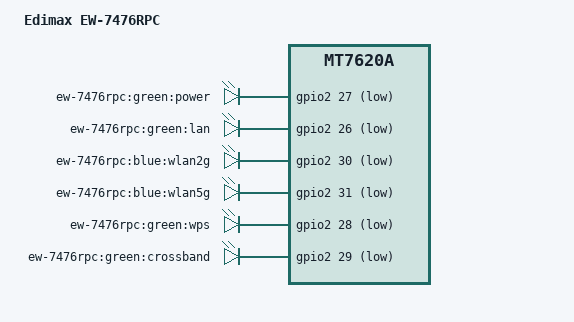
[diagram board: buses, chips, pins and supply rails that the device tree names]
// SPDX-License-Identifier: GPL-2.0-or-later OR MIT

/dts-v1/;

#include "mt7620a_edimax_ew-747x.dtsi"

/ {
	compatible = "edimax,ew-7476rpc", "ralink,mt7620a-soc";
	model = "Edimax EW-7476RPC";

	leds {
		compatible = "gpio-leds";

		led_power: power {
			label = "ew-7476rpc:green:power";
			gpios = <&gpio2 27 GPIO_ACTIVE_LOW>;
		};

		lan {
			label = "ew-7476rpc:green:lan";
			gpios = <&gpio2 26 GPIO_ACTIVE_LOW>;
		};

		wlan2g {
			label = "ew-7476rpc:blue:wlan2g";
			gpios = <&gpio2 30 GPIO_ACTIVE_LOW>;
			linux,default-trigger = "phy1radio";
		};

		wlan5g {
			label = "ew-7476rpc:blue:wlan5g";
			gpios = <&gpio2 31 GPIO_ACTIVE_LOW>;
			linux,default-trigger = "phy0radio";
		};

		wps {
			label = "ew-7476rpc:green:wps";
			gpios = <&gpio2 28 GPIO_ACTIVE_LOW>;
		};

		crossband {
			label = "ew-7476rpc:green:crossband";
			gpios = <&gpio2 29 GPIO_ACTIVE_LOW>;
		};
	};
};
